# ATSAMD10D14AS device description
Architecture: CORTEX-M0PLUS; Family: SAMD; Series: SAMD10
Registers are 32-bit, read-write, reset 0x0 unless marked. A register's access mark holds for its fields unless they carry their own. Offsets are from the block's base; [hi:lo] are bit positions; lines under a group give offsets from that group; {n}, {i} and the like mark numbered series; 'fields as' and 'values as' point back to an identical list.

## HMATRIXB — HSB Matrix
Instances: SBMATRIX 0x41007000
{0x80+8i} PRS[{i}] (i=0..15) group
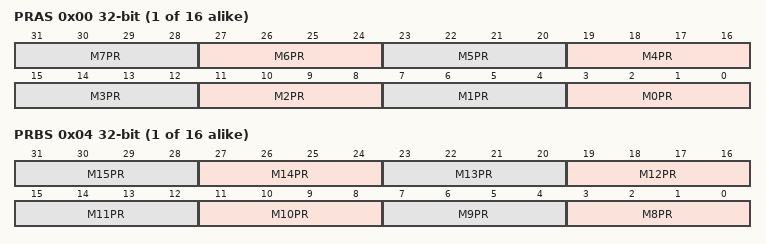
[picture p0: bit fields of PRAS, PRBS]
  0x00 PRAS — Priority A for Slave
    [4n+3:4n] M{n}PR (n=0..7) — Master {n} Priority
  0x04 PRBS — Priority B for Slave
    [4n-29:4n-32] M{n}PR (n=8..15) — Master {n} Priority
{0x110+4i} SFR[{i}] (i=0..15) — Special Function
  [31:0] SFR — Special Function Register

## MTB — Cortex-M0+ Micro-Trace Buffer
Instances: MTB 0x41006000
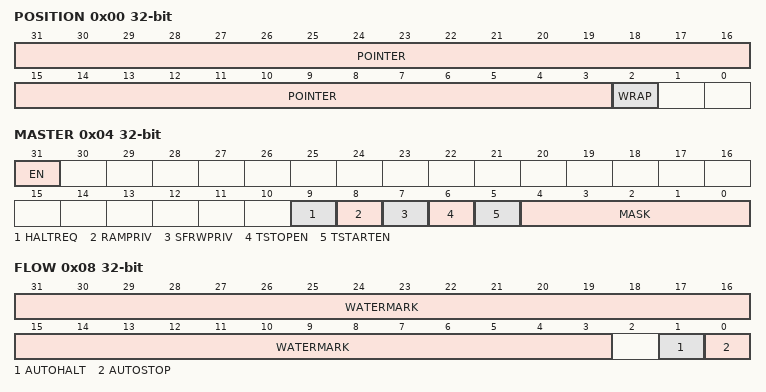
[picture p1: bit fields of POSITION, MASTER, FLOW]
0x00 POSITION reset not defined — MTB Position
  [31:3] POINTER — Trace Packet Location Pointer
  [2] WRAP — Pointer Value Wraps
0x04 MASTER — MTB Master
  [31] EN — Main Trace Enable
  [9] HALTREQ — Halt Request
  [8] RAMPRIV — SRAM Privilege
  [7] SFRWPRIV — Special Function Register Write Privilege
  [6] TSTOPEN — Trace Stop Input Enable
  [5] TSTARTEN — Trace Start Input Enable
  [4:0] MASK — Maximum Value of the Trace Buffer in SRAM
0x08 FLOW — MTB Flow
  [31:3] WATERMARK — Watermark value
  [1] AUTOHALT — Auto Halt Request
  [0] AUTOSTOP — Auto Stop Tracing
0x0C BASE ro reset not defined — MTB Base
0xF00 ITCTRL reset not defined — MTB Integration Mode Control
0xFA0 CLAIMSET reset not defined (atomic set) — MTB Claim Set
0xFA4 CLAIMCLR reset not defined (atomic clear) — MTB Claim Clear
0xFB0 LOCKACCESS reset not defined — MTB Lock Access
0xFB4 LOCKSTATUS ro reset not defined — MTB Lock Status
0xFB8 AUTHSTATUS ro reset not defined — MTB Authentication Status
0xFBC DEVARCH ro reset not defined — MTB Device Architecture
0xFC8 DEVID ro reset not defined — MTB Device Configuration
0xFCC DEVTYPE ro reset not defined — MTB Device Type
{0xFC0+4i} PID{i} ro reset not defined (i=4..7) — CoreSight
{0xFE0+4i} PID{i} ro reset not defined (i=0..3) — CoreSight
{0xFF0+4i} CID{i} ro reset not defined (i=0..3) — CoreSight

## NVMCTRL — Non-Volatile Memory Controller
Instances: NVMCTRL 0x41004000
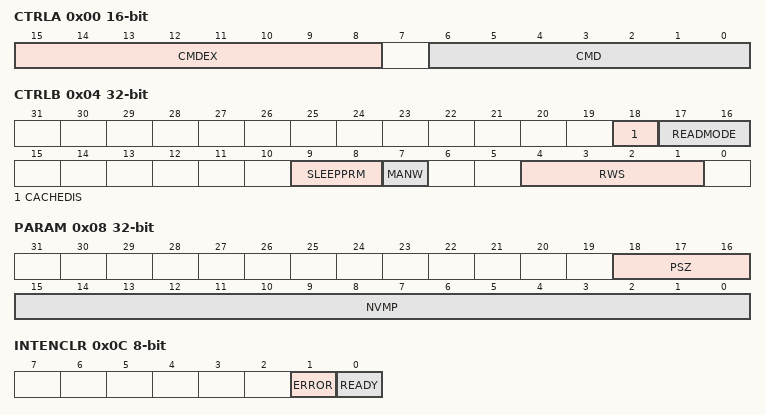
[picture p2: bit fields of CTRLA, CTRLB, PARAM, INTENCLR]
0x00 CTRLA 16-bit — Control A
  [15:8] CMDEX — Command Execution
    165=KEY (Execution Key)
  [6:0] CMD — Command
    2=ER (Erase Row - Erases the row addressed by the ADDR register.); 4=WP (Write Page - Writes the contents of the page buffer to the page addressed by the ADDR register.); 5=EAR (Erase Auxiliary Row - Erases the auxiliary row addressed by the ADDR register. This command can be given only when the security bit is not set and only to the user configuration row.); 6=WAP (Write Auxiliary Page - Writes the contents of the page buffer to the page addressed by the ADDR register. This command can be given only when the security bit is not set and only to the user configuration row.); 10=SF (Security Flow Command); 15=WL (Write lockbits); 64=LR (Lock Region - Locks the region containing the address location in the ADDR register.); 65=UR (Unlock Region - Unlocks the region containing the address location in the ADDR register.); 66=SPRM (Sets the power reduction mode.); 67=CPRM (Clears the power reduction mode.); 68=PBC (Page Buffer Clear - Clears the page buffer.); 69=SSB (Set Security Bit - Sets the security bit by writing 0x00 to the first byte in the lockbit row.); 70=INVALL (Invalidates all cache lines.)
0x04 CTRLB — Control B
  [18] CACHEDIS — Cache Disable
  [17:16] READMODE — NVMCTRL Read Mode
    0=NO_MISS_PENALTY (The NVM Controller (cache system) does not insert wait states on a cache miss. Gives the best system performance.); 1=LOW_POWER (Reduces power consumption of the cache system, but inserts a wait state each time there is a cache miss. This mode may not be relevant if CPU performance is required, as the application will be stalled and may lead to increase run time.); 2=DETERMINISTIC (The cache system ensures that a cache hit or miss takes the same amount of time, determined by the number of programmed flash wait states. This mode can be used for real-time applications that require deterministic execution timings.)
  [9:8] SLEEPPRM — Power Reduction Mode during Sleep
    0=WAKEONACCESS (NVM block enters low-power mode when entering sleep.NVM block exits low-power mode upon first access.); 1=WAKEUPINSTANT (NVM block enters low-power mode when entering sleep.NVM block exits low-power mode when exiting sleep.); 3=DISABLED (Auto power reduction disabled.)
  [7] MANW — Manual Write
  [4:1] RWS — NVM Read Wait States
    0=SINGLE (Single Auto Wait State); 1=HALF (Half Auto Wait State); 2=DUAL (Dual Auto Wait State)
0x08 PARAM — NVM Parameter
  [18:16] PSZ — Page Size
    0=8 bytes; 1=16 bytes; 2=32 bytes; 3=64 bytes; 4=128 bytes; 5=256 bytes; 6=512 bytes; 7=1024 bytes
  [15:0] NVMP — NVM Pages
0x0C INTENCLR 8-bit (atomic clear) — Interrupt Enable Clear
  [1] ERROR — Error Interrupt Enable
  [0] READY — NVM Ready Interrupt Enable
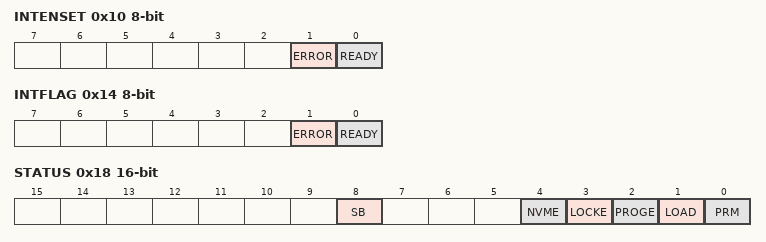
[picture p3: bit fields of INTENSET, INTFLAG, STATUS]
0x10 INTENSET 8-bit (atomic set) — Interrupt Enable Set
  fields as INTENCLR
0x14 INTFLAG 8-bit (atomic clear) — Interrupt Flag Status and Clear
  [1] ERROR
  [0] READY — NVM Ready
0x18 STATUS 16-bit
  [8] SB — Security Bit Status
  [4] NVME — NVM Error
  [3] LOCKE — Lock Error Status
  [2] PROGE — Programming Error Status
  [1] LOAD — NVM Page Buffer Active Loading
  [0] PRM — Power Reduction Mode
0x1C ADDR — Address
  [21:0] ADDR — NVM Address
0x20 LOCK 16-bit reset not defined — Lock Section
  [15:0] LOCK — Region Lock Bits

## Notices in the file
Copyright (c) 2018 Microchip Technology Inc.
SPDX-License-Identifier: Apache-2.0
Licensed under the Apache License, Version 2.0 (the "License");
you may not use this file except in compliance with the License.
You may obtain a copy of the License at
http://www.apache.org/licenses/LICENSE-2.0
Unless required by applicable law or agreed to in writing, software
distributed under the License is distributed on an "AS IS" BASIS,
WITHOUT WARRANTIES OR CONDITIONS OF ANY KIND, either express or implied.
See the License for the specific language governing permissions and
limitations under the License.
